# csi_rx_if2_VBUS2APB_WRAP_VBUSP_APB_CSI2RX register map
Vendor: Texas Instruments
Peripheral module from a debugger description file (folder J722S).
Registers are 32-bit, read-write, reset 0x0 unless marked. A register's access mark holds for its fields unless they carry their own. Offsets are as the file gives them; lines under a group give offsets from that group; [hi:lo] are bit positions; {n}, {i} and the like mark numbered series; 'fields as' and 'values as' point back to an identical list; <NAME> marks a mode.

## csi_rx_if2_VBUS2APB_WRAP_VBUSP_APB_CSI2RX
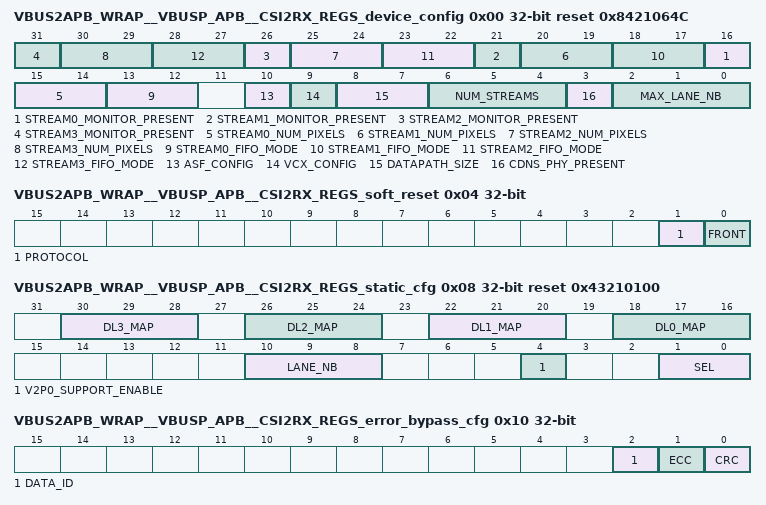
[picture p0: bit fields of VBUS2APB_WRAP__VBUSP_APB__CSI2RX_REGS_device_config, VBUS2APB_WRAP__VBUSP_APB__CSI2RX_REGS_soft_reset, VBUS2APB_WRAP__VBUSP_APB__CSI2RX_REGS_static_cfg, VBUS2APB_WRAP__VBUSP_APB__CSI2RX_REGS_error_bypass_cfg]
0x00 VBUS2APB_WRAP__VBUSP_APB__CSI2RX_REGS_device_config ro reset 0x8421064C — This register provides information related to the current configuration. This should be read by FW to determine the number of streams available and other associated parameters that will influence how the device should be controlled.
  [5n+16] STREAM{n}_MONITOR_PRESENT (n=0..3) — Pixel stream {n} Monitor present 1 = implemented
  [5n+15:5n+14] STREAM{n}_NUM_PIXELS (n=0..3) — The width of the pixel interface and the bits per pixel for the selected datatype will determine how many pixels can be output in a single cycle. Default will be 1 pixel per clock. 00 -> 1 pixel per clock 01 -> 2 pixels per clock 10 -> 4 pixels per clock 11 -> 8 pixels per clock [Reserved]
  [5n+13:5n+12] STREAM{n}_FIFO_MODE (n=0..3)
  [10] ASF_CONFIG — Additional Safety Features [ASF] Configuration: 0 = None; 1 = Full ASF.
  [9] VCX_CONFIG — Extended Virtual Channel [VCX] Configuration: 0 = 4 VCs; 1 = 16 VCs
  [8:7] DATAPATH_SIZE — Internal Datapath width 00 - 32 bit, 01 - 64bit, 10 - 16 bit, 11 - 8 Bits.
  [6:4] NUM_STREAMS — Number of Stream interfaces [1-4]
  [3] CDNS_PHY_PRESENT — Cadence DPDHY present 1 = Yes
  [2:0] MAX_LANE_NB — Max Number of Lanes [1-4]
0x04 VBUS2APB_WRAP__VBUSP_APB__CSI2RX_REGS_soft_reset access not given — CSI2 Target Controller Individual Soft Reset for Front and Protocol blocks. Writing to these registers will cause a single cycle pulse to be applied to the soft reset signals. Soft reset must only be applied when the associated clocks are running. These are used to recover from error conditions and should not be required during normal operation.
  [1] PROTOCOL — writing 1'b1 will apply a synchronous soft reset to the protocol module (access R/W1TC)
  [0] FRONT — writing 1'b1 will apply a synchronous soft reset to the Front module (access R/W1TC)
0x08 VBUS2APB_WRAP__VBUSP_APB__CSI2RX_REGS_static_cfg reset 0x43210100 — Configuration register to set the physical/logical DPHY lane mapping, the number of lanes being used, external DPHY selection and ECC support for CSI2RX v2.0. This register should be set prior to enabling the streams and must not be updated when the stream is running.
  [30:28] DL3_MAP — physical mapping of logical data lane 3
  [26:24] DL2_MAP — physical mapping of logical data lane 2.
  [22:20] DL1_MAP — physical mapping of logical data lane 1.
  [18:16] DL0_MAP — physical mapping of logical data lane 0.
  [10:8] LANE_NB — The number of lanes
  [4] V2P0_SUPPORT_ENABLE — Support extended VC, up to 16 virtual channels [4-bits] and RAW16/20. as per CSI2RX v2.0. Default is up to 4 virtual channels [3-bits] as per CSI2RX v1.3
  [1:0] SEL — selection of DPHY used as input of CSI2RX module
0x10 VBUS2APB_WRAP__VBUSP_APB__CSI2RX_REGS_error_bypass_cfg — Error detection event flag configuration. This allows various error conditions to be masked that would normally prevent data being applied to the pixel interface. This applies to ALL streams that are enabled. This register should only be modified while the datapath is disabled. In case this register is modified while the datapath is enabled, the behavior on the current frame is unpredictable. Hard reset value is 0x00000000, meaning all error masking is disabled.
  [2] DATA_ID — Enables Data ID error bypass for stream outputs. When enabled, Data ID errors in packets are signalled as interrupt events, however the data is still passed to the pixel/packed data outputs. The system must decide to mask of use the pixel data.
  [1] ECC — Enables ECC error bypass for stream outputs. When enabled, CRC errors in packets are signalled as interrupt events, however the data is still passed to the pixel/packed data outputs. The system must decide to mask of use the pixel data. NOTE:Currently not fully supported.
  [0] CRC — Enables CRC error bypass for stream outputs. When enabled, CRC errors in packets are signalled as interrupt events, however the data is still passed to the pixel/packed data outputs. The system must decide to mask of use the pixel data.
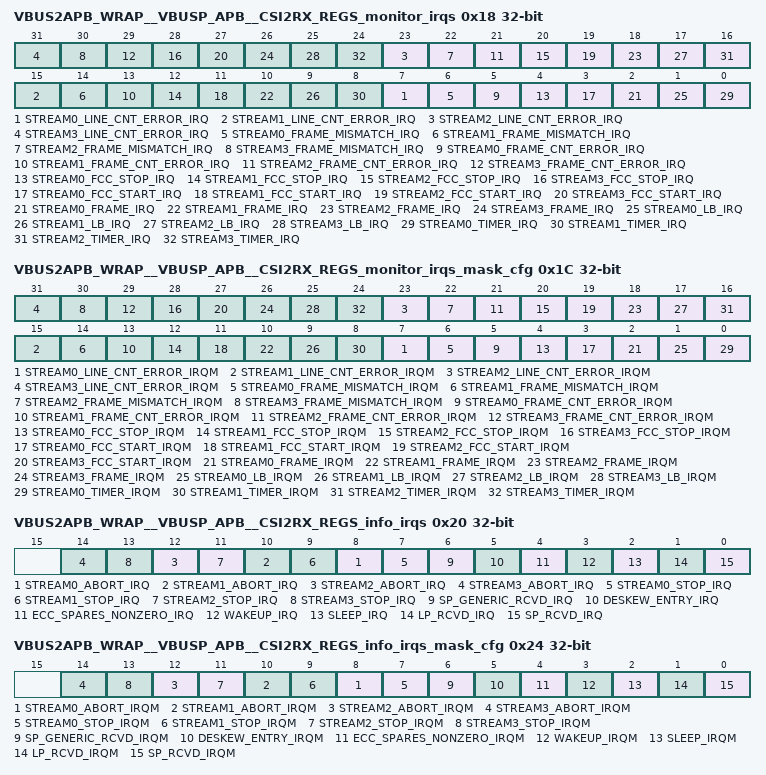
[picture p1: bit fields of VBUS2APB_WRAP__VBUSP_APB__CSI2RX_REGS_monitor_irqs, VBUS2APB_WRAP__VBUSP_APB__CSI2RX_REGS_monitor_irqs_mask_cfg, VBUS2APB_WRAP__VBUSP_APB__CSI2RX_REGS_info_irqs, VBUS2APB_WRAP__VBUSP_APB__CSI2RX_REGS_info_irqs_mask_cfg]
0x18 VBUS2APB_WRAP__VBUSP_APB__CSI2RX_REGS_monitor_irqs access not given — Information type Interrupt status (non-error conditions)
  [8n+7] STREAM{n}_LINE_CNT_ERROR_IRQ (n=0..3) — Stream {n} Line count error interrupt (access R/W1TC)
  [8n+6] STREAM{n}_FRAME_MISMATCH_IRQ (n=0..3) — Stream {n} Frame mismatch error interrupt (access R/W1TC)
  [8n+5] STREAM{n}_FRAME_CNT_ERROR_IRQ (n=0..3) — Stream {n} Frame count error interrupt (access R/W1TC)
  [8n+4] STREAM{n}_FCC_STOP_IRQ (n=0..3) — Stream {n} FCC stop interrupt (access R/W1TC)
  [8n+3] STREAM{n}_FCC_START_IRQ (n=0..3) — Stream {n} FCC start interrupt (access R/W1TC)
  [8n+2] STREAM{n}_FRAME_IRQ (n=0..3) — Stream {n} Frame interrupt (access R/W1TC)
  [8n+1] STREAM{n}_LB_IRQ (n=0..3) — Stream {n} Line/byte interrupt (access R/W1TC)
  [8n] STREAM{n}_TIMER_IRQ (n=0..3) — Stream {n} Timer interrupt (access R/W1TC)
0x1C VBUS2APB_WRAP__VBUSP_APB__CSI2RX_REGS_monitor_irqs_mask_cfg — Monitor interrupt mask. Bit addressable mask register in order to independently enable each event to trigger the monitor_irq line. Only events whose corresponding bit is set to 1 can trigger the interruption line. Hard reset is 0x00000000, i.e. interrupt line disabled
  [8n+7] STREAM{n}_LINE_CNT_ERROR_IRQM (n=0..3) — Interrupt mask for stream {n} Line count error.
  [8n+6] STREAM{n}_FRAME_MISMATCH_IRQM (n=0..3) — Interrupt mask for stream {n} Frame mismatch error.
  [8n+5] STREAM{n}_FRAME_CNT_ERROR_IRQM (n=0..3) — Interrupt mask for stream {n} Frame count error.
  [8n+4] STREAM{n}_FCC_STOP_IRQM (n=0..3) — Interrupt mask for stream {n} FCC stop.
  [8n+3] STREAM{n}_FCC_START_IRQM (n=0..3) — Interrupt mask for stream {n} FCC start.
  [8n+2] STREAM{n}_FRAME_IRQM (n=0..3) — Interrupt mask for stream {n} Frame.
  [8n+1] STREAM{n}_LB_IRQM (n=0..3) — Interrupt mask for stream {n} Line/byte.
  [8n] STREAM{n}_TIMER_IRQM (n=0..3) — Interrupt mask stream {n} Timer
0x20 VBUS2APB_WRAP__VBUSP_APB__CSI2RX_REGS_info_irqs access not given — Information type Interrupt status (non-error conditions)
  [2n+8] STREAM{n}_ABORT_IRQ (n=0..3) — Stream {n} Abort process complete. Apply a Soft reset before re-enabling the stream. (access R/W1TC)
  [2n+7] STREAM{n}_STOP_IRQ (n=0..3) — Stream {n} Stop process complete. Apply a Soft reset before re-enabling the stream. (access R/W1TC)
  [6] SP_GENERIC_RCVD_IRQ — A generic short packet has been received. (access R/W1TC)
  [5] DESKEW_ENTRY_IRQ — Either clock or any datalane has entered deskew (access R/W1TC)
  [4] ECC_SPARES_NONZERO_IRQ — Bits 7:6 of the ECC byte are non-zero. Indicates non compliance with the MIPI specification although the core will continue to operate as normal. (access R/W1TC)
  [3] WAKEUP_IRQ — Wake-up interrupt. (access R/W1TC)
  [2] SLEEP_IRQ — Sleep interrupt. (access R/W1TC)
  [1] LP_RCVD_IRQ — Long Packet received by the protocol module (access R/W1TC)
  [0] SP_RCVD_IRQ — Short Packet received by the protocol module (access R/W1TC)
0x24 VBUS2APB_WRAP__VBUSP_APB__CSI2RX_REGS_info_irqs_mask_cfg — Information interrupt mask. Bit addressable mask register in order to independently enable each event to trigger the info_irq line. Only events whose corresponding bit is set to 1 can trigger the interruption line. Hard reset is 0x00000000, i.e. interrupt line disabled
  [2n+8] STREAM{n}_ABORT_IRQM (n=0..3) — Interrupt mask for stream {n} Abort process.
  [2n+7] STREAM{n}_STOP_IRQM (n=0..3) — Interrupt mask for Stream {n} Stop process complete.
  [6] SP_GENERIC_RCVD_IRQM — Interrupt mask for Generic Short Packet received
  [5] DESKEW_ENTRY_IRQM — Interrupt mask for Deskew entry check
  [4] ECC_SPARES_NONZERO_IRQM — Interrupt mask for ECC spares check
  [3] WAKEUP_IRQM — Interrupt mask for Wake-up interrupt.
  [2] SLEEP_IRQM — Interrupt mask for Sleep interrupt.
  [1] LP_RCVD_IRQM — Interrupt mask for Long Packet received flag
  [0] SP_RCVD_IRQM — Interrupt mask for Short Packet received
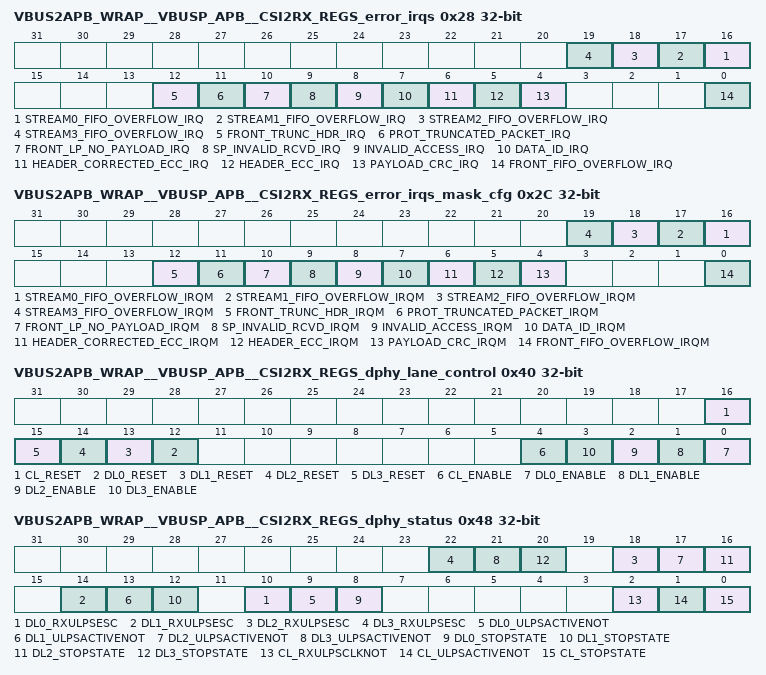
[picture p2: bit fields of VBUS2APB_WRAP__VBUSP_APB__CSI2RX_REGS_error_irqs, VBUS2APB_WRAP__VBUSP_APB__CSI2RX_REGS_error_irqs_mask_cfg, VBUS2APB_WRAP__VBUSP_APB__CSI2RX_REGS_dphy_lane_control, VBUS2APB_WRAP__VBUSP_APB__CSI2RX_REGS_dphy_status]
0x28 VBUS2APB_WRAP__VBUSP_APB__CSI2RX_REGS_error_irqs access not given — Datapath error interrupt status. Provides information about data path errors. The host processor can read the interrupt status register to identify the root cause of the event, typically after that the csi2rx_err_irq interrupt line is raised
  [n+16] STREAM{n}_FIFO_OVERFLOW_IRQ (n=0..3) — Overflow of the Stream FIFO detected: stream_fifo_overflow[{n+16}] -> Stream {n} overflow (access R/W1TC)
  [12] FRONT_TRUNC_HDR_IRQ — A truncated header [short or Long] has been received (access R/W1TC)
  [11] PROT_TRUNCATED_PACKET_IRQ — A truncated Long packet has been received. Too few/many bytes (access R/W1TC)
  [10] FRONT_LP_NO_PAYLOAD_IRQ — A truncated Long packet has been received. No payload (access R/W1TC)
  [9] SP_INVALID_RCVD_IRQ — A reserved or invalid short packet has been received (access R/W1TC)
  [8] INVALID_ACCESS_IRQ — Invalid access to the configuration register space. (access R/W1TC)
  [7] DATA_ID_IRQ — Data ID error has been detected in the header packet (access R/W1TC)
  [6] HEADER_CORRECTED_ECC_IRQ — ECC error has been detected and corrected. (access R/W1TC)
  [5] HEADER_ECC_IRQ — Unrecoverable ECC error has been detected. (access R/W1TC)
  [4] PAYLOAD_CRC_IRQ — CRC error has been detected. (access R/W1TC)
  [0] FRONT_FIFO_OVERFLOW_IRQ — Overflow detected in resynchronization FIFO between DPHY Lane Management and Protocol blocks. This will occur if sys_clk is not fast enough and should be increased since the byte clock frequency is fixed (access R/W1TC)
0x2C VBUS2APB_WRAP__VBUSP_APB__CSI2RX_REGS_error_irqs_mask_cfg — Datapath error interrupt enable Bits. This register is used to independently enable each event to trigger the err_irq interrupt line. Only events whose corresponding enable bit is set to 1 can trigger the interrupt line. Hard reset is 0x0000000, i.e. all interrupt lines are disabled
  [n+16] STREAM{n}_FIFO_OVERFLOW_IRQM (n=0..3) — Interrupt enable bit for: stream_fifo_overflow[{n+16}] -> Stream {n} overflow
  [12] FRONT_TRUNC_HDR_IRQM — Interrupt enable bit for truncated hdr.
  [11] PROT_TRUNCATED_PACKET_IRQM — Interrupt enable bit for long packet payload with too many/few bytes
  [10] FRONT_LP_NO_PAYLOAD_IRQM — Interrupt enable bit for long packet header received with no payload
  [9] SP_INVALID_RCVD_IRQM — Interrupt enable bit for invalid short packet
  [8] INVALID_ACCESS_IRQM — Interrupt enable bit for error_irqs_invalid_access.
  [7] DATA_ID_IRQM — Interrupt enable bit for error_irqs_data_id
  [6] HEADER_CORRECTED_ECC_IRQM — Interrupt enable bit for error_irqs_header_corrected_ecc
  [5] HEADER_ECC_IRQM — Interrupt enable bit for error_irqs_header_ecc
  [4] PAYLOAD_CRC_IRQM — Interrupt enable bit for error_irqs_payload_crc
  [0] FRONT_FIFO_OVERFLOW_IRQM — Interrupt enable bit for error_irqs_front_fifo_overflow
0x40 VBUS2APB_WRAP__VBUSP_APB__CSI2RX_REGS_dphy_lane_control — DPHY lane control for data and clock lanes enables and resets
  [16] CL_RESET — DPHY Clock lane Reset
  [n+12] DL{n}_RESET (n=0..3) — DPHY data lane {n} Reset
  [4] CL_ENABLE — DPHY Clock lane Enable
  [n] DL{n}_ENABLE (n=0..3) — DPHY data lane {n} Enable
0x48 VBUS2APB_WRAP__VBUSP_APB__CSI2RX_REGS_dphy_status ro — DPHY Clock and Data Lane mode status
  [4n+10] DL{n}_RXULPSESC (n=0..3) — DPHY Data lane {n} ULPS Esc
  [4n+9] DL{n}_ULPSACTIVENOT (n=0..3) — DPHY Data lane {n} ULPSActiveNot
  [4n+8] DL{n}_STOPSTATE (n=0..3) — DPHY Data lane {n} Stop State
  [2] CL_RXULPSCLKNOT — DPHY Clock lane RxULPSClkNot
  [1] CL_ULPSACTIVENOT — DPHY Clock lane ULPSActiveNot
  [0] CL_STOPSTATE — DPHY Clock lane Stop State
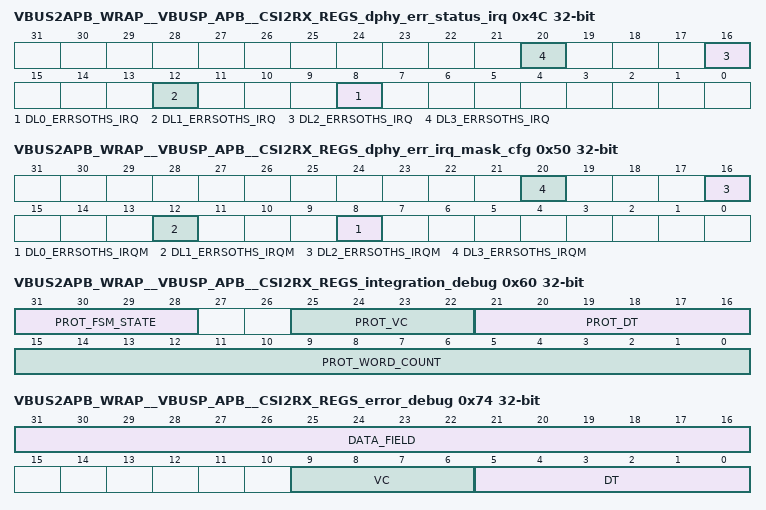
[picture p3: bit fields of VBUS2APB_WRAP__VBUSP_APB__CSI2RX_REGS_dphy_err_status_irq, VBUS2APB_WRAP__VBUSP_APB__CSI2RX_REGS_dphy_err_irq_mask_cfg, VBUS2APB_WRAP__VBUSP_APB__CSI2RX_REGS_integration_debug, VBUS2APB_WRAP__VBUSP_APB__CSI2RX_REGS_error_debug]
0x4C VBUS2APB_WRAP__VBUSP_APB__CSI2RX_REGS_dphy_err_status_irq access not given — DPHY error interrupt status
  [4n+8] DL{n}_ERRSOTHS_IRQ (n=0..3) — DPHY Data lane {n} ErrSotHS (access R/W1TC)
0x50 VBUS2APB_WRAP__VBUSP_APB__CSI2RX_REGS_dphy_err_irq_mask_cfg — DPHY error interrupt status
  [4n+8] DL{n}_ERRSOTHS_IRQM (n=0..3) — DPHY Data lane {n} ErrSotHS mask
0x60 VBUS2APB_WRAP__VBUSP_APB__CSI2RX_REGS_integration_debug ro — Used to observe the current data field, extracted by the protocol block from the last short packet data field and FSM state. FSM states are one-hot. It also indicates what data type and virtual channels were used for that short packet. This is primarily used during error condition debug. Since the data can come from asynchronous domains the data coherency cannot be relied upon.
  [31:28] PROT_FSM_STATE — csi2rx_fsm_state 0x1: WAIT_FOR_PACKET 0x2: PAYLOAD_DATA 0x4: PACKET_FOOTER_CHECK
  [25:22] PROT_VC — Protocol Virtual Channel
  [21:16] PROT_DT — Protocol Datatype
  [15:0] PROT_WORD_COUNT — Protocol Word Count [Data Field]
0x74 VBUS2APB_WRAP__VBUSP_APB__CSI2RX_REGS_error_debug ro — Error condition debug. After an error is detected by the CSI2RX, this register indicates which virtual channel, datatype and data field is impacted.
  [31:16] DATA_FIELD — Indicates the Data Field for an invalid CRC/ECC/Data ID
  [9:6] VC — Indicates the Virtual Channel for a invalid CRC/ECC/Data ID
  [5:0] DT — Indicates the Data Type for a invalid CRC/ECC/Data ID
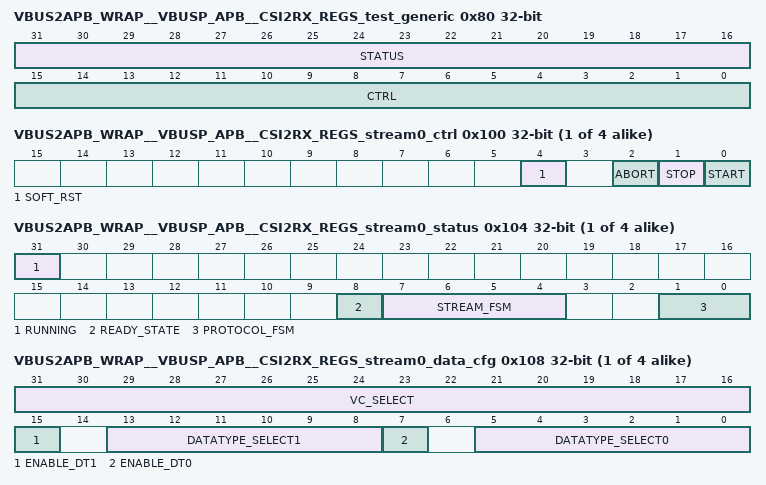
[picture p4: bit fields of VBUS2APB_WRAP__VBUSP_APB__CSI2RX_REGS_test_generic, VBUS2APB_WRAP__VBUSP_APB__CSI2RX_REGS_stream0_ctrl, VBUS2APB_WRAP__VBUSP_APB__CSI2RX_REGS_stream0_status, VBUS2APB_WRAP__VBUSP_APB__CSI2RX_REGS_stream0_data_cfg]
0x80 VBUS2APB_WRAP__VBUSP_APB__CSI2RX_REGS_test_generic access per field — Generic test control and status register that controls and reads primary I/O.
  [31:16] STATUS ro — Test status - Directly reflects, after resynchronisation into the pclk domain, the state of 'test_generic_status' primary inputs.
  [15:0] CTRL rw — Test control - Directly controls primary outputs 'test_generic_ctrl'
{0x100+0x100*i} VBUS2APB_WRAP__VBUSP_APB__CSI2RX_REGS_stream{i}_ctrl access not given (i=0..3) — CSI2RX Stream Data output datapath control. Start and Stop commands are independent for each output with the exception of pixel outputs that can never be enabled together. If a pixel output is started while the other is already running, the start command will be ignored. If both pixel outputs are enabled in a single register access, then both start commands are ignored and no pixel output is started.
  [4] SOFT_RST — Writing 1'b1 will apply a synchronous soft reset of this stream registers/FIFO (access R/W1TC)
  [2] ABORT wo — Writing 1 this register will cause the csi2rx to stop streaming on the corresponding output immediately. This may corrupt the output protocol. stream_abort_irq is generated on completion of the abort operation.
  [1] STOP wo — Writing 1 in this register will cause csi2rx to stop streaming on the corresponding output at the end of the current frame. If the command is issued during frame blanking, then the datapath will immediately stop streaming data on that output. stream_stop_irq is generated on completion of the stop operation.
  [0] START wo — Writing 1 in this register enables the corresponding datapath output. It will start streaming data at the start of the next frame that complies with the output configuration. stream_status[31] running indicates when data stream is enabled.
{0x104+0x100*i} VBUS2APB_WRAP__VBUSP_APB__CSI2RX_REGS_stream{i}_status ro (i=0..3) — CSI2 Target Controller Status. Contains useful debug information such as FSM states.
  [31] RUNNING — The Stream is enabled
  [8] READY_STATE — Indicates the state of the pushback signal pixel_ready_if for this stream
  [7:4] STREAM_FSM — Output to Stream FSM states: 0x0: STREAM_IDLE 0x1: STREAM_WAIT_CTRL_DATA // Expecting control data next 0x2: STREAM_CTRL // Check contents of Ctrl packet and extract header information 0x3: STREAM_DATA // Pixel stream pixel data unpacking 0x4: STREAM_CONV_PIX_NB // 1st cycle delay for byte2pixel conversion 0x5: STREAM_CONV_PIX_NB_EXT // 2nd cycle delay for byte2pixel conversion 0x6: STREAM_DATA_START // Assert Hsync 0x7: STREAM_DATA_END // De-assert Hysnc 0x8: STREAM_FILL_WAIT // Elastic Buffer cfg - wait until fill level is reached 0x9: STREAM_STOP // Stop at the end of Frame - used to set irq 0xA: STREAM_WAIT_CRC // Wait until CRC check has completed - Full Line cfg 0xB: STREAM_WAIT_PKT_DONE // Wait for CRC to complete before proceeding 0xC: STREAM_PKT_DONE // Packet complete - no error conditions after this point 0xD: STREAM_NULL // NULL pkt received 0xE: STREAM_FLUSH // Flush due to CRC error
  [1:0] PROTOCOL_FSM — Input to Stream FSM states: 0x0: PROT_IDLE 0x1: PROT_WAIT_CTRL 0x2: PROT_CTRL 0x3: PROT_DATA
{0x108+0x100*i} VBUS2APB_WRAP__VBUSP_APB__CSI2RX_REGS_stream{i}_data_cfg (i=0..3) — Secondary CSI2 Target Controller Data outputs configuration. This register is used to configure the data types and virtual channels are processed and output by this stream.
  [31:16] VC_SELECT — Selection of Virtual Channels to be processed: Default '0' -> All Virtual Channels are processed vc_select0[16] -> Virtual Channel Select 0 is processed vc_select1[17] -> Virtual Channel Select 1 is processed vc_select2[18] -> Virtual Channel Select 2 is processed vc_select3[19] -> Virtual Channel Select 3 is processed vc_select4[20] -> Virtual Channel Select 4 is processed vc_select5[21] -> Virtual Channel Select 5 is processed vc_select6[22] -> Virtual Channel Select 6 is processed vc_select7[23] -> Virtual Channel Select 7 is processed vc_select8[24] -> Virtual Channel Select 8 is processed vc_select9[25] -> Virtual Channel Select 9 is processed vc_select10[26] -> Virtual Channel Select 10 is processed vc_select11[27] -> Virtual Channel Select 11 is processed vc_select12[28] -> Virtual Channel Select 12 is processed vc_select13[29] -> Virtual Channel Select 13 is processed vc_select14[30] -> Virtual Channel Select 14 is processed vc_select15[31] -> Virtual Channel Select 15 is processed
  [15] ENABLE_DT1 — Enable processing of dt1
  [13:8] DATATYPE_SELECT1 — Second data type format that this stream will process
  [7] ENABLE_DT0 — Enable processing of dt0
  [5:0] DATATYPE_SELECT0 — First data type format that this stream will process
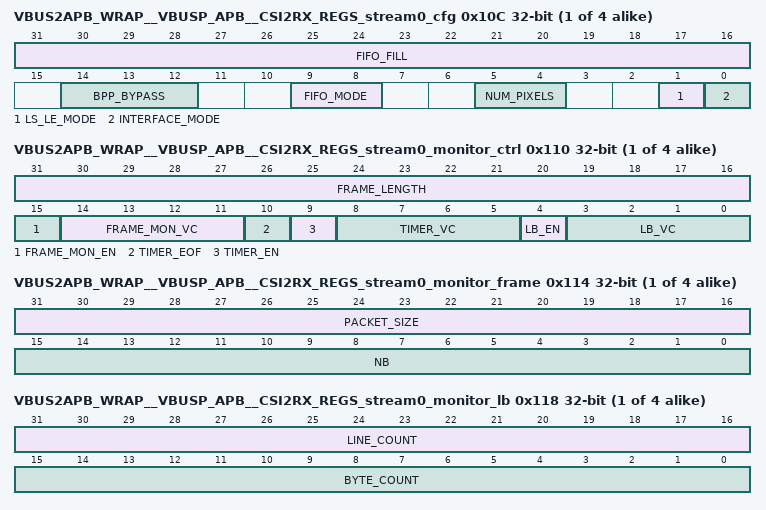
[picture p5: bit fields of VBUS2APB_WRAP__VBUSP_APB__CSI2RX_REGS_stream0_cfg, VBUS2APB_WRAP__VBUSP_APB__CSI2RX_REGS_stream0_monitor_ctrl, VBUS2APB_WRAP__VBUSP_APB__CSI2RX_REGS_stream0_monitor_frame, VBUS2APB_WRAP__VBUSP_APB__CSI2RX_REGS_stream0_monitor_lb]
{0x10C+0x100*i} VBUS2APB_WRAP__VBUSP_APB__CSI2RX_REGS_stream{i}_cfg (i=0..3) — Primary CSI2 Target Controller Data pixel outputs configuration. This register is used to configure the output mode. It is also used to set up some Stream FIFO related settings.
  [31:16] FIFO_FILL — Set the FIFO_FILL_LEVEL which is used to hold data in the FIFO until this level is reached before allow data to be pulled. This setting is only used when fifo_mode is set for Large Buffer operation
  [14:12] BPP_BYPASS — Force unpacking of any Data type as selected RAW type. 0 - No bypass 1 - unpack as RAW6 2 - unpack as RAW7 3 - unpack as RAW8 4 - unpack as RAW10 5 - unpack as RAW12 6 - unpack as RAW14 7 - unpack as RAW16
  [9:8] FIFO_MODE — Stream FIFO configuration, which must be set in accordance to FIFO sizing, flow control and the relationship between the link and pixel interface data rates. Refer to Use Case descriptions for further guidance on FIFO sizing and valid stream configuration options. 00: Full Line Buffer. Hold data in FIFO until CRC check completes. 01: Large Buffer [Fill Level Controlled]. Hold data in FIFO until FIFO_FILL_LEVEL is reached. 1x: Short Buffer. When pixel output data rate can match link data rate, a small buffer can be used to accommodate CDC, pixel data packing, and data rate matching
  [5:4] NUM_PIXELS — Number of pixels to output from the stream. Valid values are 1, 2, 4 and 8. The width of the pixel interface and the bits per pixel for the selected datatype will determine how many pixels can be output in a single cycle. Default will be 1 pixel per clock. 00 -> 1 pixel per clock 01 -> 2 pixels per clock 10 -> 4 pixels per clock 11 -> 8 pixels per clock [Reserved]
  [1] LS_LE_MODE — Enable LS/LE control of HYSNC_VALID output. By default, LS and LE short packets are not required and HYSC_VALID will be generated from the start and end of payload data.
  [0] INTERFACE_MODE — Select the output configuration. Pixel = 0 [default] Packed = 1
{0x110+0x100*i} VBUS2APB_WRAP__VBUSP_APB__CSI2RX_REGS_stream{i}_monitor_ctrl (i=0..3) — Stream Monitor configuration. This register is used to configure the CSI2RX Monitors: Programmable Frame monitor to trigger an event if a truncated frame is detected, Programmable Timer to trigger an event based on a clock cycle counter after a frame start or frame end, Programmable line/byte counters to trigger an event at a specific byte in a line. This register is used to enable/disable CSI2RX programmable interrupt, select the virtual channel for each programmable IT and select the point which will trigger the event. This register should not be modified while the data path is enabled, nor should any of settings be changed when the respective monitor/counter/timer is enabled. In these cases, the behaviour is unpredictable. Hard reset value is 0x00000000, all interrupt generators disabled on Virtual Channel 0.
  [31:16] FRAME_LENGTH — Indicates the frame length in lines to detect truncated frames. This value must not change while monitor is enabled, i.e. it must only be changed when the frame_mon_en bit is low. 0x0000 means truncated frame detection feature disabled
  [15] FRAME_MON_EN — Enables monitor. This bit must only be set high after the frame_mon_vc and frame_length have been set.
  [14:11] FRAME_MON_VC — Indicates virtual channel for monitor. This value must not change while monitor is enabled, i.e. it must only be changed when the frame_mon_en bit is low.
  [10] TIMER_EOF — Select the starting point of the timer: 0x0: Start of Frame event on selected virtual channel 0x1: End of Frame event on selected virtual channel. This value must not change while timer_en is enabled
  [9] TIMER_EN — Enables timer based interrupt. This bit must only be set high after the timer_eof and timer_vc have been set.
  [8:5] TIMER_VC — Indicates which VC should be used to generate timer based interrupt. This value must not change while timer_en is enabled.
  [4] LB_EN — Enables line/byte counter. This bit must only be set high after the lb_vc, line_count and byte_count have been set.
  [3:0] LB_VC — Indicates which VC should be used to generate line/byte counter interrupt. This value must not change while lb_en is enabled
{0x114+0x100*i} VBUS2APB_WRAP__VBUSP_APB__CSI2RX_REGS_stream{i}_monitor_frame ro (i=0..3) — Stream Monitor Frame. Used to observe the current frame number and packet size on monitored virtual channels. These values are extracted by the CSI2RX from the last frame start short packet data field.
  [31:16] PACKET_SIZE — Size of the current payload
  [15:0] NB — Number of the last frame processed.
{0x118+0x100*i} VBUS2APB_WRAP__VBUSP_APB__CSI2RX_REGS_stream{i}_monitor_lb (i=0..3) — Stream Monitor Line. Used to specify the byte and line numbers that will generate an interrupt. This register must only be modified when the corresponding line/byte enable is disabled.
  [31:16] LINE_COUNT — Indicates the line number to generate an interrupt. [First line of a Frame is line number 0]
  [15:0] BYTE_COUNT — Indicates the byte number of the line to generate an interrupt. [First byte of a line is byte number 0]
{0x11C+0x100*i} VBUS2APB_WRAP__VBUSP_APB__CSI2RX_REGS_stream{i}_timer (i=0..3) — Stream Timer. Used to specify the number of clock cycles until the interrupt is triggered after frame start or frame end. This register must only be modified when the corresponding timer enable is disabled.
  [24:0] COUNT — Number of clock cycles
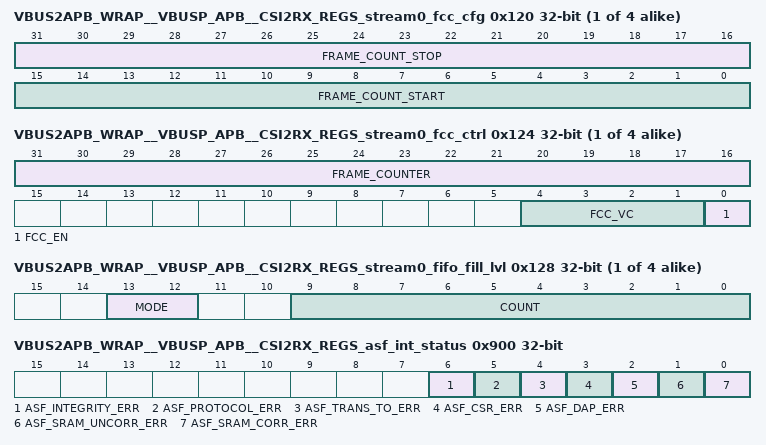
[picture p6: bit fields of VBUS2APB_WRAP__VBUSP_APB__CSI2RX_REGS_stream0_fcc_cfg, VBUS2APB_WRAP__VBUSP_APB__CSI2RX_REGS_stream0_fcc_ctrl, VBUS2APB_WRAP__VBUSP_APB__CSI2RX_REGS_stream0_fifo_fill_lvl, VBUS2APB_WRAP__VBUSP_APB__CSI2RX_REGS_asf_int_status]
{0x120+0x100*i} VBUS2APB_WRAP__VBUSP_APB__CSI2RX_REGS_stream{i}_fcc_cfg (i=0..3) — Stream Frame Capture Control configuration. Used to specify the frame count value when when the CSI2RX must generate interrupts FCC_START and FCC_STOP. This register must only be modified when the corresponding frame count enable is disabled.
  [31:16] FRAME_COUNT_STOP — Indicates the frame number on which the interrupt should be generated and the stream will stop outputting data on the pixel interface. [0x0000 will be continuous frames.]
  [15:0] FRAME_COUNT_START — Indicates the frame number on which the interrupt should be generated and the stream will start outputting data on the pixel interface. [0x0000 will be the current frame.]
{0x124+0x100*i} VBUS2APB_WRAP__VBUSP_APB__CSI2RX_REGS_stream{i}_fcc_ctrl access per field (i=0..3) — Stream Frame Capture Counter control. Used to enable / disable the FCC and specify which virtual channel it should operate on.
  [31:16] FRAME_COUNTER ro — Current Frame number being processed
  [4:1] FCC_VC rw — Indicates which VC should be used to generate FCC interrupts. This value must not change while fcc_en is enabled
  [0] FCC_EN rw — Frame Capture Counter enable.
{0x128+0x100*i} VBUS2APB_WRAP__VBUSP_APB__CSI2RX_REGS_stream{i}_fifo_fill_lvl access per field (i=0..3) — Stream FIFO fill level monitor. This can operate in 2 modes: 1 - Monitor peak fill level until the stream is stopped. 2 - Monitor peak fill level when the first FIFO read is made during a frame.
  [13:12] MODE rw — 00 -> Fill level detection disabled 01 -> Mode 1 10 -> Mode 2 11 -> Reserved
  [9:0] COUNT ro — Peak fill level of FIFO.
0x900 VBUS2APB_WRAP__VBUSP_APB__CSI2RX_REGS_asf_int_status access not given — ASF Interrupt Status Register. This register indicates the source of ASF interrupts. The corresponding bit in the mask register must be clear for a bit to be set. If any bit is set in this register the asf_int_fatal or asf_int_nonfatal signal will be asserted. Writing to either raw or masked status registers, clear both registers. For test purposes, trigger signal interrupt event by writing to the ASF interrupt status test register.
  [6] ASF_INTEGRITY_ERR — Integrity error interrupt (access R/W1TC)
  [5] ASF_PROTOCOL_ERR — Protocol error interrupt (access R/W1TC)
  [4] ASF_TRANS_TO_ERR — Transaction timeouts error interrupt (access R/W1TC)
  [3] ASF_CSR_ERR — Configuration and status registers error interrupt (access R/W1TC)
  [2] ASF_DAP_ERR — Data and address paths parity error interrupt (access R/W1TC)
  [1] ASF_SRAM_UNCORR_ERR — SRAM uncorrectable error interrupt (access R/W1TC)
  [0] ASF_SRAM_CORR_ERR — SRAM correctable error interrupt (access R/W1TC)
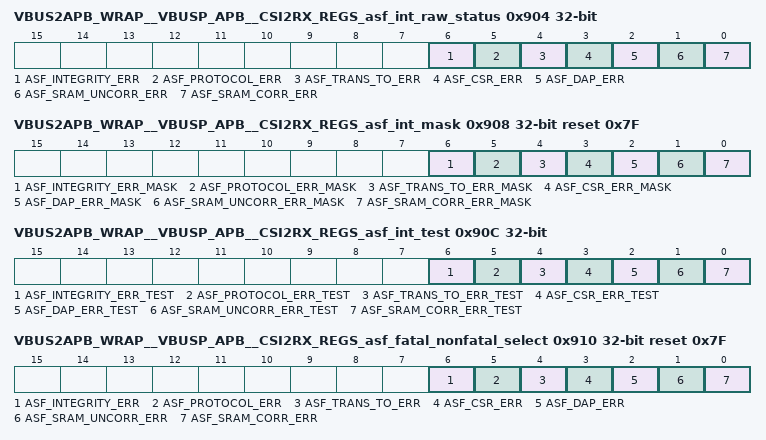
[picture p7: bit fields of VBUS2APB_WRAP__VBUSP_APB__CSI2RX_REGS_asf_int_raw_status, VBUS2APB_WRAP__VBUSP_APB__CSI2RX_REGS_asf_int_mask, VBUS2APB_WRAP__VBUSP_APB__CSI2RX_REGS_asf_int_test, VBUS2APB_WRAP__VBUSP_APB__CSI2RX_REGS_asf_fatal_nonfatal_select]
0x904 VBUS2APB_WRAP__VBUSP_APB__CSI2RX_REGS_asf_int_raw_status access not given — ASF Interrupt Raw Status Register. A bit set in this raw register indicates a source of ASF fault in the corresponding feature. Writing to either raw or masked status registers, clear both registers. For test purposes, trigger signal interrupt event by writing to the ASF interrupt status test register.
  fields as VBUS2APB_WRAP__VBUSP_APB__CSI2RX_REGS_asf_int_status
0x908 VBUS2APB_WRAP__VBUSP_APB__CSI2RX_REGS_asf_int_mask access not given reset 0x7F — The ASF interrupt mask register indicating which interrupt bits in the ASF interrupt status register are masked. All bits are set at reset. Clear the individual bit to enable the corresponding interrupt.
  [6] ASF_INTEGRITY_ERR_MASK rw — Mask bit for integrity error interrupt
  [5] ASF_PROTOCOL_ERR_MASK rw — Mask bit for protocol error interrupt.
  [4] ASF_TRANS_TO_ERR_MASK rw — Mask bit for transaction timeouts error interrupt.
  [3] ASF_CSR_ERR_MASK rw — Mask bit for configuration and status registers error interrupt.
  [2] ASF_DAP_ERR_MASK rw — Mask bit for data and address paths parity error interrupt.
  [1] ASF_SRAM_UNCORR_ERR_MASK rw — Mask bit for SRAM uncorrectable error interrupt.
  [0] ASF_SRAM_CORR_ERR_MASK rw — Mask bit for SRAM correctable error interrupt.
0x90C VBUS2APB_WRAP__VBUSP_APB__CSI2RX_REGS_asf_int_test access not given — The ASF interrupt test register emulate hardware even. Write one to individual bit to trigger single event in (masked and raw) status registers according to mask and will generate interrupt accordingly.
  [6] ASF_INTEGRITY_ERR_TEST wo — Test bit for integrity error interrupt
  [5] ASF_PROTOCOL_ERR_TEST wo — Test bit for protocol error interrupt.
  [4] ASF_TRANS_TO_ERR_TEST wo — Test bit for transaction timeouts error interrupt.
  [3] ASF_CSR_ERR_TEST wo — Test bit for configuration and status registers error interrupt.
  [2] ASF_DAP_ERR_TEST wo — Test bit for data and address paths parity error interrupt.
  [1] ASF_SRAM_UNCORR_ERR_TEST wo — Test bit for SRAM uncorrectable error interrupt.
  [0] ASF_SRAM_CORR_ERR_TEST wo — Test bit for SRAM correctable error interrupt.
0x910 VBUS2APB_WRAP__VBUSP_APB__CSI2RX_REGS_asf_fatal_nonfatal_select access not given reset 0x7F — The fatal or non-fatal interrupt register selects whether a fatal (asf_int_fatal) or non-fatal (asf_int_nonfatal) interrupt is triggered. If the bit of the event will be set to one then fatal interrupt (asf_int_fatal) will be triggered. Otherwise the non-fatal interrupt (asf_int_nonfatal) will be triggered.
  [6] ASF_INTEGRITY_ERR rw — Enable integrity error interrupt as fatal
  [5] ASF_PROTOCOL_ERR rw — Enable protocol error interrupt as fatal.
  [4] ASF_TRANS_TO_ERR rw — Enable transaction timeouts error interrupt as fatal.
  [3] ASF_CSR_ERR rw — Enable configuration and status registers error interrupt as fatal.
  [2] ASF_DAP_ERR rw — Enable data and address paths parity error interrupt as fatal.
  [1] ASF_SRAM_UNCORR_ERR rw — Enable SRAM uncorrectable error interrupt as fatal.
  [0] ASF_SRAM_CORR_ERR rw — Enable SRAM correctable error interrupt as fatal.
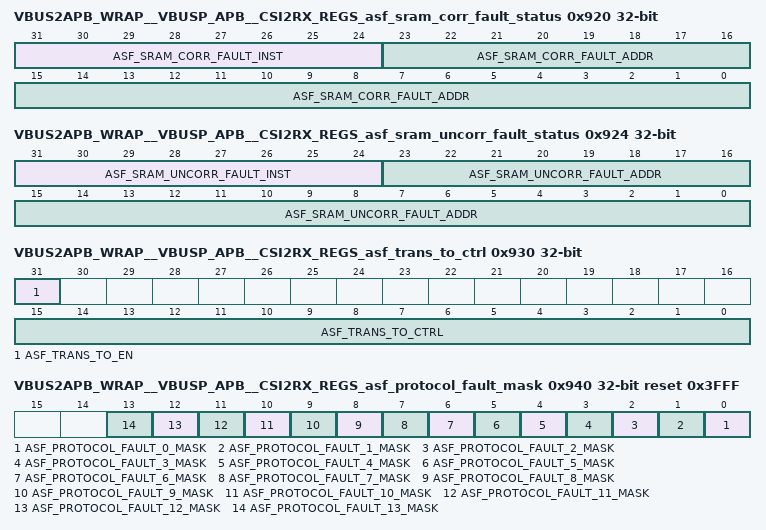
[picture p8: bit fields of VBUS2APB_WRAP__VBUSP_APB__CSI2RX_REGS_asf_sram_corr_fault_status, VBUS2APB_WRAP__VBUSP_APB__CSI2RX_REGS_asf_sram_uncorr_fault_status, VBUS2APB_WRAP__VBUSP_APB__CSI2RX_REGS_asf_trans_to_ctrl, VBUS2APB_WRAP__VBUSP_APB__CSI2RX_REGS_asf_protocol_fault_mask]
0x920 VBUS2APB_WRAP__VBUSP_APB__CSI2RX_REGS_asf_sram_corr_fault_status ro — Status register for SRAM correctable fault. These fields are updated whenever asf_sram_corr_fault input is active.
  [31:24] ASF_SRAM_CORR_FAULT_INST — Last SRAM instance that generated fault.
  [23:0] ASF_SRAM_CORR_FAULT_ADDR — Last SRAM address that generated fault.
0x924 VBUS2APB_WRAP__VBUSP_APB__CSI2RX_REGS_asf_sram_uncorr_fault_status ro — Status register for SRAM uncorrectable fault. These fields are updated whenever asf_sram_uncorr_fault input is active.
  [31:24] ASF_SRAM_UNCORR_FAULT_INST — Last SRAM instance that generated fault.
  [23:0] ASF_SRAM_UNCORR_FAULT_ADDR — Last SRAM address that generated fault.
0x928 VBUS2APB_WRAP__VBUSP_APB__CSI2RX_REGS_asf_sram_fault_stats access not given — Statistics register for SRAM faults. Note that this register clears when software writes to any field.
  [15:0] ASF_SRAM_FAULT_CORR_STATS — Count of number of correctable errors if implemented. Count value will saturate at 0xffff. (access R/W1TC)
0x930 VBUS2APB_WRAP__VBUSP_APB__CSI2RX_REGS_asf_trans_to_ctrl — Control register to configure the ASF transaction timeout monitors.
  [31] ASF_TRANS_TO_EN — Enable transaction timeout monitoring.
  [15:0] ASF_TRANS_TO_CTRL — Timer value to use for transaction timeout monitor.
0x934 VBUS2APB_WRAP__VBUSP_APB__CSI2RX_REGS_asf_trans_to_fault_mask reset 0x1 — Control register to mask out ASF transaction timeout faults from triggering interrupts. On reset, all bits are set to mask out all sources. Clear the corresponding bit to enable the interrupt source. The width of this field is parameterisable and the bit definitions are implementation specific.
  [0] ASF_TRANS_TO_FAULT_0_MASK — Mask register for each ASF transaction timeout fault source.
0x938 VBUS2APB_WRAP__VBUSP_APB__CSI2RX_REGS_asf_trans_to_fault_status access not given — Status register for transaction timeouts fault. If a fault occurs the revelant status bit will be set to 1. Each bit can be cleared by software writing 1 to each bit.
  [0] ASF_TRANS_TO_FAULT_0_STATUS — Status bits for transaction timeouts faults. (access R/W1TC)
0x940 VBUS2APB_WRAP__VBUSP_APB__CSI2RX_REGS_asf_protocol_fault_mask reset 0x3FFF — Control register to mask out ASF Protocol faults from triggering interrupts. On reset, all bits are set to mask out all sources. Clear the corresponding bit to enable the interrupt source. The width of this field is parameterisable and the bit definitions are implementation specific.
  [n] ASF_PROTOCOL_FAULT_{n}_MASK (n=0..13) — Mask register for each ASF protocol fault source.
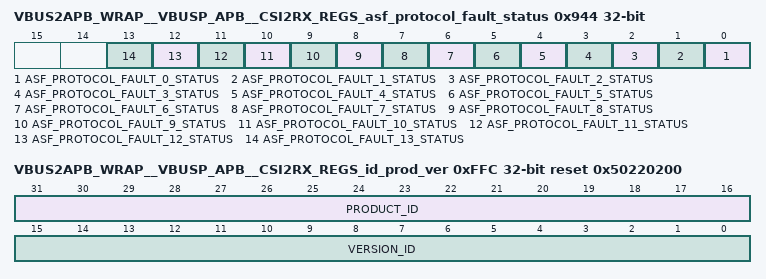
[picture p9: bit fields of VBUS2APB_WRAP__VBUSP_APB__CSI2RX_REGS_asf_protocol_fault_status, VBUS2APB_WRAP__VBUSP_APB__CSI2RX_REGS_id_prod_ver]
0x944 VBUS2APB_WRAP__VBUSP_APB__CSI2RX_REGS_asf_protocol_fault_status access not given — Status register for protocol faults. If a fault occurs the revelant status bit will be set to 1. Each bit can be cleared by software writing 1 to each bit
  [n] ASF_PROTOCOL_FAULT_{n}_STATUS (n=0..13) — Status bits for protocol faults. (access R/W1TC)
0xFFC VBUS2APB_WRAP__VBUSP_APB__CSI2RX_REGS_id_prod_ver ro reset 0x50220200 — This register is hard-coded in order to allow software to identify the product and its release version. The product ID will be fixed for all versions, while the version will be updated as new releases for the CSI2RX product are made.
  [31:16] PRODUCT_ID — Product Identification Number [IP5022/IP5022A].
  [15:0] VERSION_ID — Product Version Number [R200].
